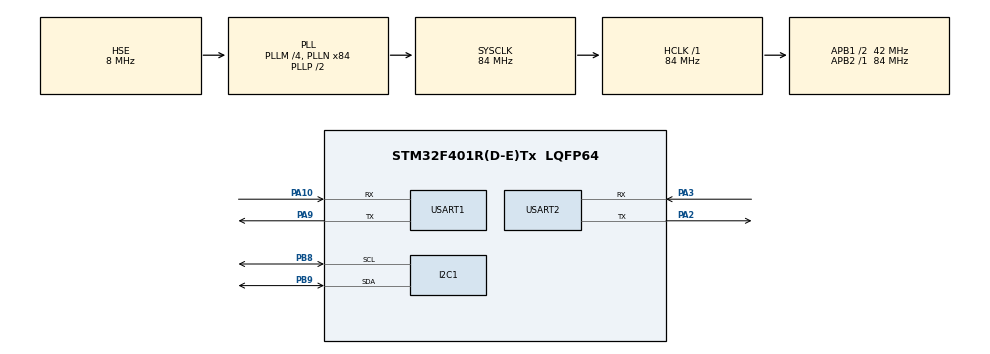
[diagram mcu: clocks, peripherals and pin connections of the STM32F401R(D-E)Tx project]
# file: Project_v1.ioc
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Mcu.Family=STM32F4
Mcu.Name=STM32F401R(D-E)Tx
Mcu.Package=LQFP64
NVIC.PriorityGroup=NVIC_PRIORITYGROUP_4
PA10.Mode=Asynchronous
PA10.Signal=USART1_RX
PA13.Mode=Serial_Wire
PA13.Signal=SYS_JTMS-SWDIO
PA14.Mode=Serial_Wire
PA14.Signal=SYS_JTCK-SWCLK
PA2.Mode=Asynchronous
PA2.Signal=USART2_TX
PA3.Mode=Asynchronous
PA3.Signal=USART2_RX
PA9.Mode=Asynchronous
PA9.Signal=USART1_TX
PB8.Mode=I2C
PB8.Signal=I2C1_SCL
PB9.Mode=I2C
PB9.Signal=I2C1_SDA
PH0\ -\ OSC_IN.Mode=HSE-External-Clock-Source
PH0\ -\ OSC_IN.Signal=RCC_OSC_IN
PH1\ -\ OSC_OUT.Mode=HSE-External-Clock-Source
PH1\ -\ OSC_OUT.Signal=RCC_OSC_OUT
ProjectManager.HeapSize=0x200
ProjectManager.StackSize=0x400
ProjectManager.TargetToolchain=MDK-ARM V5.32
RCC.48MHZClocksFreq_Value=42000000
RCC.AHBFreq_Value=84000000
RCC.APB1CLKDivider=RCC_HCLK_DIV2
RCC.APB1Freq_Value=42000000
RCC.APB1TimFreq_Value=84000000
RCC.APB2Freq_Value=84000000
RCC.APB2TimFreq_Value=84000000
RCC.CortexFreq_Value=84000000
RCC.HCLKFreq_Value=84000000
RCC.HSE_VALUE=8000000
RCC.HSI_VALUE=16000000
RCC.LSE_VALUE=32768
RCC.PLLM=4
RCC.PLLN=84
RCC.PLLSourceVirtual=RCC_PLLSOURCE_HSE
RCC.SYSCLKFreq_VALUE=84000000
RCC.SYSCLKSource=RCC_SYSCLKSOURCE_PLLCLK
RCC.VCOOutputFreq_Value=168000000
USART1.VirtualMode=VM_ASYNC
USART2.VirtualMode=VM_ASYNC
board=custom

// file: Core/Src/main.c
/* USER CODE BEGIN Header */
/**
  ******************************************************************************
  * @file           : main.c
  * @brief          : Main program body
  ******************************************************************************
  * @attention
  *
  * Copyright (c) 2026 STMicroelectronics.
  * All rights reserved.
  *
  * This software is licensed under terms that can be found in the LICENSE file
  * in the root directory of this software component.
  * If no LICENSE file comes with this software, it is provided AS-IS.
  *
  ******************************************************************************
  */
/* USER CODE END Header */
#include "main.h"

/* USER CODE BEGIN Includes */

#include "bme280.h"
#include <stdio.h>

/* USER CODE END Includes */

I2C_HandleTypeDef hi2c1;

UART_HandleTypeDef huart1;
UART_HandleTypeDef huart2;

/* USER CODE BEGIN PV */

struct bme280_dev bme280;
uint8_t dev_addr = (0x76 << 1);
uint8_t chip_id = 0;
HAL_StatusTypeDef i2c_status;
HAL_StatusTypeDef device_status;
uint8_t calib_data[6] = {0};
HAL_StatusTypeDef calib_status;
int8_t bme280_rslt;
struct bme280_settings settings;
struct bme280_data sensor_data;
char json_buffer[128];
int json_length;

/* USER CODE END PV */

void SystemClock_Config(void);
static void MX_GPIO_Init(void);
static void MX_I2C1_Init(void);
static void MX_USART2_UART_Init(void);
static void MX_USART1_UART_Init(void);
/* USER CODE BEGIN PFP */

int8_t BME280_Read(uint8_t reg_addr, uint8_t *reg_data,
                   uint32_t len, void *intf_ptr);

int8_t BME280_Write(uint8_t reg_addr, const uint8_t *reg_data,
                    uint32_t len, void *intf_ptr);

void BME280_Delay(uint32_t period, void *intf_ptr);

/* USER CODE END PFP */

int main(void)
{

  /* MCU Configuration--------------------------------------------------------*/

  /* Reset of all peripherals, Initializes the Flash interface and the Systick. */
  HAL_Init();

  /* Configure the system clock */
  SystemClock_Config();

  /* Initialize all configured peripherals */
  MX_GPIO_Init();
  MX_I2C1_Init();
  MX_USART2_UART_Init();
  MX_USART1_UART_Init();
  /* USER CODE BEGIN 2 */

bme280.intf = BME280_I2C_INTF;
bme280.intf_ptr = &hi2c1;

bme280.read = BME280_Read;
bme280.write = BME280_Write;
bme280.delay_us = BME280_Delay;

bme280_rslt = bme280_init(&bme280);

settings.osr_t = BME280_OVERSAMPLING_2X;
settings.osr_p = BME280_OVERSAMPLING_2X;
settings.osr_h = BME280_OVERSAMPLING_1X;

settings.filter = BME280_FILTER_COEFF_2;
settings.standby_time = BME280_STANDBY_TIME_1000_MS;

bme280_rslt = bme280_set_sensor_settings(
    BME280_SEL_ALL_SETTINGS,
    &settings,
    &bme280
);

bme280_rslt = bme280_set_sensor_mode(
    BME280_POWERMODE_NORMAL,
    &bme280
);

  /* USER CODE END 2 */

  /* Infinite loop */
  /* USER CODE BEGIN WHILE */
  while (1)
  {
		bme280_rslt = bme280_get_sensor_data(
        BME280_ALL,
        &sensor_data,
        &bme280
    );

		json_length = snprintf(
    json_buffer,
    sizeof(json_buffer),
    "{\"status\":\"success\",\"temperature\":%.2f,\"humidity\":%.2f,\"pressure\":%.2f}\r\n",
    sensor_data.temperature,
    sensor_data.humidity,
    sensor_data.pressure / 100.0
);

		HAL_UART_Transmit(
    &huart2,
    (uint8_t *)json_buffer,
    json_length,
    HAL_MAX_DELAY
);

		HAL_UART_Transmit(
    &huart1,
    (uint8_t *)json_buffer,
    json_length,
    HAL_MAX_DELAY
);

    HAL_Delay(1000);
    /* USER CODE END WHILE */

  }
}

void SystemClock_Config(void)
{
  RCC_OscInitTypeDef RCC_OscInitStruct = {0};
  RCC_ClkInitTypeDef RCC_ClkInitStruct = {0};

  /** Configure the main internal regulator output voltage
  */
  __HAL_RCC_PWR_CLK_ENABLE();
  __HAL_PWR_VOLTAGESCALING_CONFIG(PWR_REGULATOR_VOLTAGE_SCALE2);

  /** Initializes the RCC Oscillators according to the specified parameters
  * in the RCC_OscInitTypeDef structure.
  */
  RCC_OscInitStruct.OscillatorType = RCC_OSCILLATORTYPE_HSE;
  RCC_OscInitStruct.HSEState = RCC_HSE_BYPASS;
  RCC_OscInitStruct.PLL.PLLState = RCC_PLL_ON;
  RCC_OscInitStruct.PLL.PLLSource = RCC_PLLSOURCE_HSE;
  RCC_OscInitStruct.PLL.PLLM = 4;
  RCC_OscInitStruct.PLL.PLLN = 84;
  RCC_OscInitStruct.PLL.PLLP = RCC_PLLP_DIV2;
  RCC_OscInitStruct.PLL.PLLQ = 4;
  if (HAL_RCC_OscConfig(&RCC_OscInitStruct) != HAL_OK)
  {
    Error_Handler();
  }

  /** Initializes the CPU, AHB and APB buses clocks
  */
  RCC_ClkInitStruct.ClockType = RCC_CLOCKTYPE_HCLK|RCC_CLOCKTYPE_SYSCLK
                              |RCC_CLOCKTYPE_PCLK1|RCC_CLOCKTYPE_PCLK2;
  RCC_ClkInitStruct.SYSCLKSource = RCC_SYSCLKSOURCE_PLLCLK;
  RCC_ClkInitStruct.AHBCLKDivider = RCC_SYSCLK_DIV1;
  RCC_ClkInitStruct.APB1CLKDivider = RCC_HCLK_DIV2;
  RCC_ClkInitStruct.APB2CLKDivider = RCC_HCLK_DIV1;

  if (HAL_RCC_ClockConfig(&RCC_ClkInitStruct, FLASH_LATENCY_2) != HAL_OK)
  {
    Error_Handler();
  }
}

static void MX_I2C1_Init(void)
{

  hi2c1.Instance = I2C1;
  hi2c1.Init.ClockSpeed = 100000;
  hi2c1.Init.DutyCycle = I2C_DUTYCYCLE_2;
  hi2c1.Init.OwnAddress1 = 0;
  hi2c1.Init.AddressingMode = I2C_ADDRESSINGMODE_7BIT;
  hi2c1.Init.DualAddressMode = I2C_DUALADDRESS_DISABLE;
  hi2c1.Init.OwnAddress2 = 0;
  hi2c1.Init.GeneralCallMode = I2C_GENERALCALL_DISABLE;
  hi2c1.Init.NoStretchMode = I2C_NOSTRETCH_DISABLE;
  if (HAL_I2C_Init(&hi2c1) != HAL_OK)
  {
    Error_Handler();
  }

}

static void MX_USART1_UART_Init(void)
{

  huart1.Instance = USART1;
  huart1.Init.BaudRate = 115200;
  huart1.Init.WordLength = UART_WORDLENGTH_8B;
  huart1.Init.StopBits = UART_STOPBITS_1;
  huart1.Init.Parity = UART_PARITY_NONE;
  huart1.Init.Mode = UART_MODE_TX_RX;
  huart1.Init.HwFlowCtl = UART_HWCONTROL_NONE;
  huart1.Init.OverSampling = UART_OVERSAMPLING_16;
  if (HAL_UART_Init(&huart1) != HAL_OK)
  {
    Error_Handler();
  }

}

static void MX_USART2_UART_Init(void)
{

  huart2.Instance = USART2;
  huart2.Init.BaudRate = 115200;
  huart2.Init.WordLength = UART_WORDLENGTH_8B;
  huart2.Init.StopBits = UART_STOPBITS_1;
  huart2.Init.Parity = UART_PARITY_NONE;
  huart2.Init.Mode = UART_MODE_TX_RX;
  huart2.Init.HwFlowCtl = UART_HWCONTROL_NONE;
  huart2.Init.OverSampling = UART_OVERSAMPLING_16;
  if (HAL_UART_Init(&huart2) != HAL_OK)
  {
    Error_Handler();
  }

}

static void MX_GPIO_Init(void)
{
  GPIO_InitTypeDef GPIO_InitStruct = {0};

  /* GPIO Ports Clock Enable */
  __HAL_RCC_GPIOH_CLK_ENABLE();
  __HAL_RCC_GPIOA_CLK_ENABLE();
  __HAL_RCC_GPIOB_CLK_ENABLE();

  /* Configure PA5 as output for onboard LED */
  GPIO_InitStruct.Pin = GPIO_PIN_5;
  GPIO_InitStruct.Mode = GPIO_MODE_OUTPUT_PP;
  GPIO_InitStruct.Pull = GPIO_NOPULL;
  GPIO_InitStruct.Speed = GPIO_SPEED_FREQ_LOW;

  HAL_GPIO_Init(GPIOA, &GPIO_InitStruct);

}

/* USER CODE BEGIN 4 */

int8_t BME280_Read(
    uint8_t reg_addr,
    uint8_t *reg_data,
    uint32_t len,
    void *intf_ptr
)
{
    I2C_HandleTypeDef *i2c = (I2C_HandleTypeDef *)intf_ptr;

    HAL_StatusTypeDef status;

    status = HAL_I2C_Mem_Read(
        i2c,
        dev_addr,
        reg_addr,
        I2C_MEMADD_SIZE_8BIT,
        reg_data,
        len,
        100
    );

    if (status == HAL_OK)
    {
        return 0;
    }
    else
    {
        return -1;
    }
}

int8_t BME280_Write(
    uint8_t reg_addr,
    const uint8_t *reg_data,
    uint32_t len,
    void *intf_ptr
)
{
    I2C_HandleTypeDef *i2c = (I2C_HandleTypeDef *)intf_ptr;

    HAL_StatusTypeDef status;

    status = HAL_I2C_Mem_Write(
        i2c,
        dev_addr,
        reg_addr,
        I2C_MEMADD_SIZE_8BIT,
        (uint8_t *)reg_data,
        len,
        100
    );

    if (status == HAL_OK)
    {
        return 0;
    }
    else
    {
        return -1;
    }
}

void BME280_Delay(uint32_t period, void *intf_ptr)
{
    (void)intf_ptr;

    HAL_Delay((period + 999) / 1000);
}

/* USER CODE END 4 */

void Error_Handler(void)
{
  __disable_irq();
  while (1)
  {
  }
}
